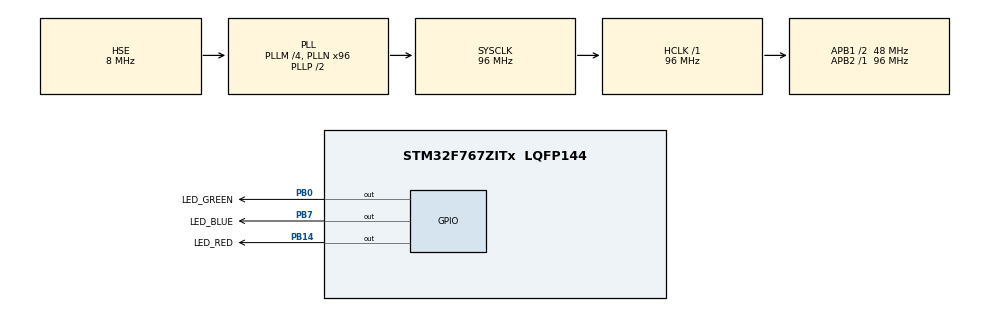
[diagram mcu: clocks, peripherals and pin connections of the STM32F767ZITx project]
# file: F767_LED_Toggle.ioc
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Mcu.Family=STM32F7
Mcu.Name=STM32F767ZITx
Mcu.Package=LQFP144
NVIC.PriorityGroup=NVIC_PRIORITYGROUP_4
PA13.Mode=Serial_Wire
PA13.Signal=SYS_JTMS-SWDIO
PA14.GPIO_Label=TCK
PA14.Mode=Serial_Wire
PA14.Signal=SYS_JTCK-SWCLK
PB0.GPIO_Label=LED_GREEN
PB0.Signal=GPIO_Output
PB14.GPIO_Label=LED_RED
PB14.Signal=GPIO_Output
PB3.GPIO_Label=SWO
PB3.Signal=SYS_JTDO-SWO
PB7.GPIO_Label=LED_BLUE
PB7.Signal=GPIO_Output
PC14/OSC32_IN.Mode=LSE-External-Oscillator
PC14/OSC32_IN.Signal=RCC_OSC32_IN
PC15/OSC32_OUT.Mode=LSE-External-Oscillator
PC15/OSC32_OUT.Signal=RCC_OSC32_OUT
PH0/OSC_IN.GPIO_Label=MCO [STM32F103CBT6_PA8]
PH0/OSC_IN.Mode=HSE-External-Clock-Source
PH0/OSC_IN.Signal=RCC_OSC_IN
PH1/OSC_OUT.Mode=HSE-External-Clock-Source
PH1/OSC_OUT.Signal=RCC_OSC_OUT
ProjectManager.HeapSize=0x200
ProjectManager.StackSize=0x400
ProjectManager.TargetToolchain=STM32CubeIDE
RCC.48MHZClocksFreq_Value=24000000
RCC.AHBFreq_Value=96000000
RCC.APB1CLKDivider=RCC_HCLK_DIV2
RCC.APB1Freq_Value=48000000
RCC.APB1TimFreq_Value=96000000
RCC.APB2Freq_Value=96000000
RCC.APB2TimFreq_Value=96000000
RCC.CortexFreq_Value=96000000
RCC.HCLKFreq_Value=96000000
RCC.HSE_VALUE=8000000
RCC.HSI_VALUE=16000000
RCC.PLLM=4
RCC.PLLMUL=RCC_PLL_MUL9
RCC.PLLN=96
RCC.PLLQ=4
RCC.PLLSourceVirtual=RCC_PLLSOURCE_HSE
RCC.PRESCALERUSB=RCC_USBCLKSOURCE_PLL_DIV1_5
RCC.SYSCLKFreq_VALUE=96000000
RCC.SYSCLKSource=RCC_SYSCLKSOURCE_PLLCLK
RCC.SYSCLKSourceVirtual=RCC_SYSCLKSOURCE_PLLCLK
RCC.USBFreq_Value=48000000
RCC.VCOOutputFreq_Value=192000000
board=NUCLEO-F767ZI

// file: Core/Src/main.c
/* USER CODE BEGIN Header */
/**
  ******************************************************************************
  * @file           : main.c
  * @brief          : Main program body
  ******************************************************************************
  * @attention
  *
  * Copyright (c) 2024 STMicroelectronics.
  * All rights reserved.
  *
  * This software is licensed under terms that can be found in the LICENSE file
  * in the root directory of this software component.
  * If no LICENSE file comes with this software, it is provided AS-IS.
  *
  ******************************************************************************
  */
/* USER CODE END Header */
#include "main.h"

/* USER CODE BEGIN PTD */
typedef enum {
  LED_BLUE,
  LED_GREEN,
  LED_RED
} LED_Type;

typedef enum {
  OFF,
  ON
} LED_State;

typedef struct {
  LED_Type type;
  LED_State state;
} LED_Status;

LED_Status current_led;

/* USER CODE END PTD */

void SystemClock_Config(void);
static void MX_GPIO_Init(void);
/* USER CODE BEGIN PFP */

void LED_toggle();

/* USER CODE END PFP */

int main(void)
{

  /* MCU Configuration--------------------------------------------------------*/

  /* Reset of all peripherals, Initializes the Flash interface and the Systick. */
  HAL_Init();

  /* Configure the system clock */
  SystemClock_Config();

  /* Initialize all configured peripherals */
  MX_GPIO_Init();

  /* Infinite loop */
  /* USER CODE BEGIN WHILE */
  while (1)
  {

    LED_toggle();
    /* USER CODE END WHILE */

  }
}

void SystemClock_Config(void)
{
  RCC_OscInitTypeDef RCC_OscInitStruct = {0};
  RCC_ClkInitTypeDef RCC_ClkInitStruct = {0};

  /** Configure LSE Drive Capability
  */
  HAL_PWR_EnableBkUpAccess();

  /** Configure the main internal regulator output voltage
  */
  __HAL_RCC_PWR_CLK_ENABLE();
  __HAL_PWR_VOLTAGESCALING_CONFIG(PWR_REGULATOR_VOLTAGE_SCALE3);

  /** Initializes the RCC Oscillators according to the specified parameters
  * in the RCC_OscInitTypeDef structure.
  */
  RCC_OscInitStruct.OscillatorType = RCC_OSCILLATORTYPE_HSE;
  RCC_OscInitStruct.HSEState = RCC_HSE_BYPASS;
  RCC_OscInitStruct.PLL.PLLState = RCC_PLL_ON;
  RCC_OscInitStruct.PLL.PLLSource = RCC_PLLSOURCE_HSE;
  RCC_OscInitStruct.PLL.PLLM = 4;
  RCC_OscInitStruct.PLL.PLLN = 96;
  RCC_OscInitStruct.PLL.PLLP = RCC_PLLP_DIV2;
  RCC_OscInitStruct.PLL.PLLQ = 4;
  RCC_OscInitStruct.PLL.PLLR = 2;
  if (HAL_RCC_OscConfig(&RCC_OscInitStruct) != HAL_OK)
  {
    Error_Handler();
  }

  /** Activate the Over-Drive mode
  */
  if (HAL_PWREx_EnableOverDrive() != HAL_OK)
  {
    Error_Handler();
  }

  /** Initializes the CPU, AHB and APB buses clocks
  */
  RCC_ClkInitStruct.ClockType = RCC_CLOCKTYPE_HCLK|RCC_CLOCKTYPE_SYSCLK
                              |RCC_CLOCKTYPE_PCLK1|RCC_CLOCKTYPE_PCLK2;
  RCC_ClkInitStruct.SYSCLKSource = RCC_SYSCLKSOURCE_PLLCLK;
  RCC_ClkInitStruct.AHBCLKDivider = RCC_SYSCLK_DIV1;
  RCC_ClkInitStruct.APB1CLKDivider = RCC_HCLK_DIV2;
  RCC_ClkInitStruct.APB2CLKDivider = RCC_HCLK_DIV1;

  if (HAL_RCC_ClockConfig(&RCC_ClkInitStruct, FLASH_LATENCY_3) != HAL_OK)
  {
    Error_Handler();
  }
}

static void MX_GPIO_Init(void)
{
  GPIO_InitTypeDef GPIO_InitStruct = {0};

  /* GPIO Ports Clock Enable */
  __HAL_RCC_GPIOC_CLK_ENABLE();
  __HAL_RCC_GPIOH_CLK_ENABLE();
  __HAL_RCC_GPIOB_CLK_ENABLE();
  __HAL_RCC_GPIOA_CLK_ENABLE();

  /*Configure GPIO pin Output Level */
  HAL_GPIO_WritePin(GPIOB, LED_GREEN_Pin|LED_RED_Pin|LED_BLUE_Pin, GPIO_PIN_RESET);

  /*Configure GPIO pins : LED_GREEN_Pin LED_RED_Pin LED_BLUE_Pin */
  GPIO_InitStruct.Pin = LED_GREEN_Pin|LED_RED_Pin|LED_BLUE_Pin;
  GPIO_InitStruct.Mode = GPIO_MODE_OUTPUT_PP;
  GPIO_InitStruct.Pull = GPIO_NOPULL;
  GPIO_InitStruct.Speed = GPIO_SPEED_FREQ_LOW;
  HAL_GPIO_Init(GPIOB, &GPIO_InitStruct);

}

/* USER CODE BEGIN 4 */

void LED_toggle()
{

  current_led.type = LED_BLUE;
  HAL_GPIO_TogglePin(GPIOB, LED_BLUE_Pin);
  current_led.state = HAL_GPIO_ReadPin(GPIOB, LED_BLUE_Pin) == GPIO_PIN_SET ? ON:OFF;
  HAL_Delay(100);

  current_led.type = LED_GREEN;
  HAL_GPIO_TogglePin(GPIOB, LED_GREEN_Pin);
  current_led.state = HAL_GPIO_ReadPin(GPIOB, LED_GREEN_Pin) == GPIO_PIN_SET ? ON:OFF;
  HAL_Delay(100);

  current_led.type = LED_RED;
  HAL_GPIO_TogglePin(GPIOB, LED_RED_Pin);
  current_led.state = HAL_GPIO_ReadPin(GPIOB, LED_RED_Pin) == GPIO_PIN_SET ? ON:OFF;
  HAL_Delay(100);
}

/* USER CODE END 4 */

void Error_Handler(void)
{
  __disable_irq();
  while (1)
  {
  }
}
